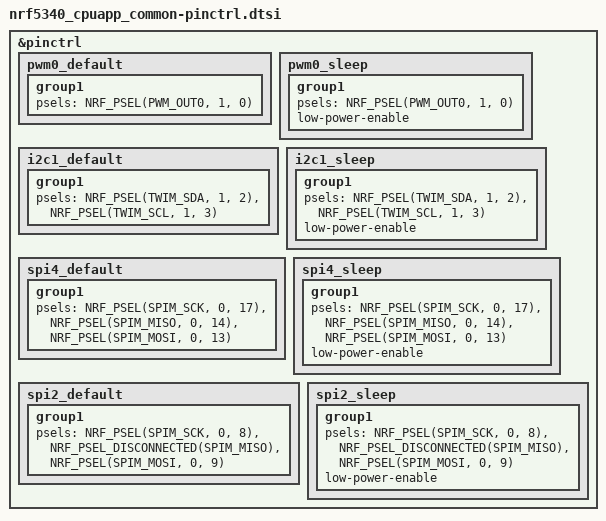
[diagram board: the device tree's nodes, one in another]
/*
 * Copyright (c) 2022 Nordic Semiconductor
 * SPDX-License-Identifier: Apache-2.0
 */

&pinctrl {
	pwm0_default: pwm0_default {
		group1 {
			psels = <NRF_PSEL(PWM_OUT0, 1, 0)>;
		};
	};

	pwm0_sleep: pwm0_sleep {
		group1 {
			psels = <NRF_PSEL(PWM_OUT0, 1, 0)>;
			low-power-enable;
		};
	};

	i2c1_default: i2c1_default {
		group1 {
			psels = <NRF_PSEL(TWIM_SDA, 1, 2)>,
				<NRF_PSEL(TWIM_SCL, 1, 3)>;
		};
	};

	i2c1_sleep: i2c1_sleep {
		group1 {
			psels = <NRF_PSEL(TWIM_SDA, 1, 2)>,
				<NRF_PSEL(TWIM_SCL, 1, 3)>;
			low-power-enable;
		};
	};

	spi4_default: spi4_default {
		group1 {
			psels = <NRF_PSEL(SPIM_SCK, 0, 17)>,
				<NRF_PSEL(SPIM_MISO, 0, 14)>,
				<NRF_PSEL(SPIM_MOSI, 0, 13)>;
		};
	};

	spi4_sleep: spi4_sleep {
		group1 {
			psels = <NRF_PSEL(SPIM_SCK, 0, 17)>,
				<NRF_PSEL(SPIM_MISO, 0, 14)>,
				<NRF_PSEL(SPIM_MOSI, 0, 13)>;
			low-power-enable;
		};
	};

	spi2_default: spi2_default {
		group1 {
			psels = <NRF_PSEL(SPIM_SCK, 0, 8)>,
				<NRF_PSEL_DISCONNECTED(SPIM_MISO)>,
				<NRF_PSEL(SPIM_MOSI, 0, 9)>;
		};
	};

	spi2_sleep: spi2_sleep {
		group1 {
			psels = <NRF_PSEL(SPIM_SCK, 0, 8)>,
				<NRF_PSEL_DISCONNECTED(SPIM_MISO)>,
				<NRF_PSEL(SPIM_MOSI, 0, 9)>;
			low-power-enable;
		};
	};

};
